VERSION "2027-draft-2026-10-23"

NS_ :

BS_:

BU_: DEI MIKA TopShellLighting
VAL_TABLE_ EnableDisable 1 "Enabled" 0 "Disabled" ;
VAL_TABLE_ OnOff 1 "On" 0 "Off" ;
VAL_TABLE_ FaultState 1 "Fault" 0 "OK" ;
VAL_TABLE_ WarningState 1 "Warning" 0 "NoWarning" ;
VAL_TABLE_ DeviceStatus 2 "Waiting" 1 "Fault" 0 "OK" ;
VAL_TABLE_ Permission 1 "Allowed" 0 "NotAllowed" ;
VAL_TABLE_ Connection 1 "Connected" 0 "Disconnected" ;
VAL_TABLE_ BalancingMode 2 "Manual" 1 "Automatic" 0 "Off" ;
VAL_TABLE_ BalancingState 4 "BlockedOrFault" 3 "Complete" 2 "Paused" 1 "Balancing" 0 "Off" ;
VAL_TABLE_ BalancingBlockReason 7 "Other" 6 "BPSFault" 5 "Communication" 4 "VehicleState" 3 "CellVoltage" 2 "ChipTemperature" 1 "CellTemperature" 0 "None" ;
VAL_TABLE_ ServerConnection 1 "Connected" 0 "Disconnected/Retrying" ;
VAL_TABLE_ Pressed 1 "Pressed" 0 "NotPressed" ;
VAL_TABLE_ Validity 1 "Valid" 0 "Invalid" ;
VAL_TABLE_ Watchdog 1 "TimedOut" 0 "Alive" ;
VAL_TABLE_ NormalAdvanced 1 "Advanced" 0 "Normal" ;
VAL_TABLE_ MotorCommandSource 1 "External" 0 "VCU" ;
VAL_TABLE_ Gear 3 "Invalid" 2 "Reverse" 1 "Forward" 0 "Neutral" ;
VAL_TABLE_ BPSFaultSummary 5 "SMBFault" 4 "PrechargeFault" 3 "ContactorRelayFault" 2 "EmergencyStop" 1 "SetpointFault" 0 "OK" ;
VAL_TABLE_ VCUState 7 "VehicleNotReady" 6 "Disabled" 5 "CruiseControl" 4 "Regen" 3 "ReverseDrive" 2 "NeutralDrive" 1 "ForwardDrive" 0 "Init" ;
VAL_TABLE_ ChargeState 2 "Charging" 1 "Standby" 0 "Disabled" ;
VAL_TABLE_ EVSEState 5 "F_EVSEFault" 4 "E_Fault" 3 "D_VentilationRequired" 2 "C_ChargingReady" 1 "B_Connected" 0 "A_Disconnected" ;
VAL_TABLE_ GPSAntennaState 3 "Unknown" 2 "ShortCircuit" 1 "OpenCircuit" 0 "OK" ;
VAL_TABLE_ GPSFix 2 "Fix3D" 1 "Fix2D" 0 "NoFix" ;
VAL_TABLE_ CellularTechnology 4 "Other" 3 "NB_IoT" 2 "LTE_M" 1 "LTE" 0 "None" ;
VAL_TABLE_ TPEEControlMode 2 "ConstantInputVoltage" 1 "PerturbAndObserve" 0 "Disabled" ;
VAL_TABLE_ TPEEOperatingMode 7 "Fault" 6 "MinimumInputVoltage" 5 "TemperatureDerating" 4 "ConstantOutputCurrent" 3 "ConstantOutputVoltage" 2 "MinimumInputCurrent" 1 "ConstantInputCurrent" 0 "ConstantInputVoltage" ;
VAL_TABLE_ TPEEFault 8 "Fault" 7 "PhaseOverCurrent" 6 "InputUnderCurrent" 5 "InputOverCurrent" 4 "OutputOverCurrent" 3 "OutputOverVoltage" 2 "InputOverVoltage" 1 "ConfigurationError" 0 "OK" ;
VAL_TABLE_ LWSCalibration 1 "Calibrated" 0 "NotCalibrated" ;
VAL_TABLE_ LWSTrim 1 "Trimmed" 0 "NotTrimmed" ;
VAL_TABLE_ LWSCommand 5 "ResetCalibration" 3 "SetAngleZero" ;
VAL_TABLE_ ElconControl 1 "Disable" 0 "Charge" ;
VAL_TABLE_ ElconMuxPage 5 "Page5" 4 "Page4" 3 "Page3" 2 "Page2" 1 "Page1" ;

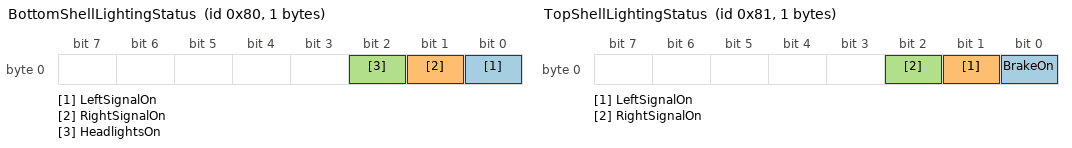
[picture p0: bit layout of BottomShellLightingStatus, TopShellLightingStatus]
BO_ 128 BottomShellLightingStatus: 1 DEI
 SG_ LeftSignalOn : 0|1@1+ (1,0) [0.0|1.0] "" Vector__XXX
 SG_ RightSignalOn : 1|1@1+ (1,0) [0.0|1.0] "" Vector__XXX
 SG_ HeadlightsOn : 2|1@1+ (1,0) [0.0|1.0] "" Vector__XXX

BO_ 129 TopShellLightingStatus: 1 TopShellLighting
 SG_ BrakeOn : 0|1@1+ (1,0) [0.0|1.0] "" Vector__XXX
 SG_ LeftSignalOn : 1|1@1+ (1,0) [0.0|1.0] "" Vector__XXX
 SG_ RightSignalOn : 2|1@1+ (1,0) [0.0|1.0] "" Vector__XXX

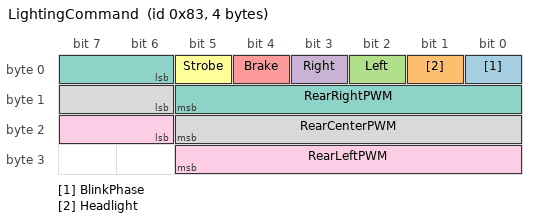
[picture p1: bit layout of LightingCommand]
BO_ 131 LightingCommand: 4 DEI
 SG_ BlinkPhase : 0|1@1+ (1,0) [0.0|1.0] "" Vector__XXX
 SG_ Headlight : 1|1@1+ (1,0) [0.0|1.0] "" Vector__XXX
 SG_ Left : 2|1@1+ (1,0) [0.0|1.0] "" Vector__XXX
 SG_ Right : 3|1@1+ (1,0) [0.0|1.0] "" Vector__XXX
 SG_ Brake : 4|1@1+ (1,0) [0.0|1.0] "" Vector__XXX
 SG_ Strobe : 5|1@1+ (1,0) [0.0|1.0] "" Vector__XXX
 SG_ RearRightPWM : 6|8@1+ (1,0) [0|255] "" Vector__XXX
 SG_ RearCenterPWM : 14|8@1+ (1,0) [0|255] "" Vector__XXX
 SG_ RearLeftPWM : 22|8@1+ (1,0) [0|255] "" Vector__XXX

CM_ BO_ 128 "Bottom-shell lighting circuitry is integrated on DEI; DEI transmits this status. No separate BottomShellLighting CAN node.";
CM_ SG_ 128 HeadlightsOn "HeadlightsOn";
CM_ SG_ 128 RightSignalOn "RightSignalOn";
CM_ SG_ 128 LeftSignalOn "LeftSignalOn";
CM_ BO_ 129 "2027 team-defined layout; physical values use the shared scaling conventions.";
CM_ SG_ 129 RightSignalOn "RightSignalOn";
CM_ SG_ 129 LeftSignalOn "LeftSignalOn";
CM_ SG_ 129 BrakeOn "BrakeOn";
CM_ BO_ 131 "Cyclic lighting commands from DEI; rear PWM raw counts are 0-255.";
CM_ SG_ 131 RearLeftPWM "PWM command: 0 = off, 255 = full duty.";
CM_ SG_ 131 RearCenterPWM "PWM command: 0 = off, 255 = full duty.";
CM_ SG_ 131 RearRightPWM "PWM command: 0 = off, 255 = full duty.";
CM_ SG_ 131 Strobe "Strobe lighting command.";
CM_ SG_ 131 Brake "Brake lighting command.";
CM_ SG_ 131 Right "Right lighting command.";
CM_ SG_ 131 Left "Left lighting command.";
CM_ SG_ 131 Headlight "Headlight lighting command.";
CM_ SG_ 131 BlinkPhase "Blink phase used to synchronize flashing lights.";
BA_DEF_ SG_  "ValueTable" STRING ;
BA_DEF_ BO_  "LayoutPending" INT 0 1;
BA_DEF_ BO_  "ProtocolSource" STRING ;
BA_DEF_  "BusType" STRING ;
BA_DEF_  "DBName" STRING ;
BA_DEF_ BO_  "VFrameFormat" ENUM  "StandardCAN","ExtendedCAN","reserved","J1939PG","reserved","reserved","reserved","reserved","reserved","reserved","reserved","reserved","reserved","reserved","StandardCAN_FD","ExtendedCAN_FD";
BA_DEF_ BO_  "CANFD_BRS" ENUM  "0","1";
BA_DEF_ BO_  "GenMsgSendType" ENUM  "Cyclic","Triggered","None";
BA_DEF_ BO_  "GenMsgCycleTime" INT 0 65535;
BA_DEF_  "Baudrate" INT 1 10000000;
BA_DEF_DEF_  "ValueTable" "";
BA_DEF_DEF_  "LayoutPending" 0;
BA_DEF_DEF_  "ProtocolSource" "";
BA_DEF_DEF_  "BusType" "CAN";
BA_DEF_DEF_  "DBName" "";
BA_DEF_DEF_  "VFrameFormat" "StandardCAN";
BA_DEF_DEF_  "CANFD_BRS" "0";
BA_DEF_DEF_  "GenMsgSendType" "Cyclic";
BA_DEF_DEF_  "GenMsgCycleTime" 0;
BA_ "DBName" "LightingCAN";
BA_ "Baudrate" 250000;
BA_ "ProtocolSource" BO_ 128 "2027 allocation draft";
BA_ "GenMsgCycleTime" BO_ 128 200;
BA_ "ValueTable" SG_ 128 HeadlightsOn "OnOff";
BA_ "ValueTable" SG_ 128 RightSignalOn "OnOff";
BA_ "ValueTable" SG_ 128 LeftSignalOn "OnOff";
BA_ "ProtocolSource" BO_ 129 "2027 allocation draft";
BA_ "GenMsgCycleTime" BO_ 129 200;
BA_ "ValueTable" SG_ 129 RightSignalOn "OnOff";
BA_ "ValueTable" SG_ 129 LeftSignalOn "OnOff";
BA_ "ValueTable" SG_ 129 BrakeOn "OnOff";
BA_ "ProtocolSource" BO_ 131 "2027 allocation draft";
BA_ "GenMsgCycleTime" BO_ 131 200;
BA_ "ValueTable" SG_ 131 Strobe "OnOff";
BA_ "ValueTable" SG_ 131 Brake "OnOff";
BA_ "ValueTable" SG_ 131 Right "OnOff";
BA_ "ValueTable" SG_ 131 Left "OnOff";
BA_ "ValueTable" SG_ 131 Headlight "OnOff";
BA_ "ValueTable" SG_ 131 BlinkPhase "OnOff";
VAL_ 128 HeadlightsOn 0 "Off" 1 "On" ;
VAL_ 128 RightSignalOn 0 "Off" 1 "On" ;
VAL_ 128 LeftSignalOn 0 "Off" 1 "On" ;
VAL_ 129 RightSignalOn 0 "Off" 1 "On" ;
VAL_ 129 LeftSignalOn 0 "Off" 1 "On" ;
VAL_ 129 BrakeOn 0 "Off" 1 "On" ;
VAL_ 131 Strobe 0 "Off" 1 "On" ;
VAL_ 131 Brake 0 "Off" 1 "On" ;
VAL_ 131 Right 0 "Off" 1 "On" ;
VAL_ 131 Left 0 "Off" 1 "On" ;
VAL_ 131 Headlight 0 "Off" 1 "On" ;
VAL_ 131 BlinkPhase 0 "Off" 1 "On" ;
